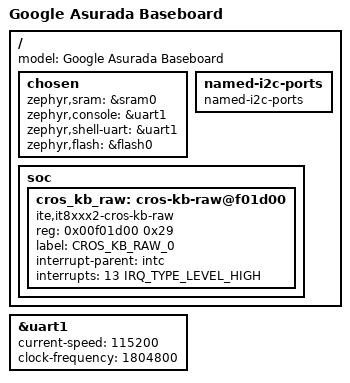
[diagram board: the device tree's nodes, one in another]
/* Copyright 2021 The Chromium OS Authors. All rights reserved.
 * Use of this source code is governed by a BSD-style license that can be
 * found in the LICENSE file.
 */

/dts-v1/;

#include <cros/ite/it8xxx2.dtsi>
#include <dt-bindings/gpio_defines.h>
#include <it8xxx2.dtsi>

/ {
	model = "Google Asurada Baseboard";

	chosen {
		zephyr,sram = &sram0;
		zephyr,console = &uart1;
		zephyr,shell-uart = &uart1;
		zephyr,flash = &flash0;
	};

	named-i2c-ports {
		compatible = "named-i2c-ports";
	};

	soc {
		cros_kb_raw: cros-kb-raw@f01d00 {
			compatible = "ite,it8xxx2-cros-kb-raw";
			reg = <0x00f01d00 0x29>;
			label = "CROS_KB_RAW_0";
			interrupt-parent = <&intc>;
			interrupts = <13 IRQ_TYPE_LEVEL_HIGH>;
			status = "disabled";
		};
	};
};

&uart1 {
	status = "okay";
	current-speed = <115200>;
	clock-frequency = <1804800>;
};

&cros_kb_raw {
	status = "okay";
};
